AUTOSAR XML (schema 00051)
package /MyReceivingSWC
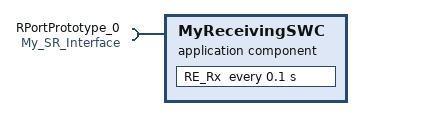
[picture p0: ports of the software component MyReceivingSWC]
  application sw component type MyReceivingSWC
    require port RPortPrototype_0: required-interface=My_SR_Interface
    behavior RxSwcInternalBehavior: data-type-mapping=MyDataTypeMappingSet, supports-multiple-instantiation=true
      timing event TE_RX: start-on-event=RE_Rx, period=0.1
      runnable RE_Rx: symbol=RE_Rx_func
        data-read-access:
          access DRA_DE_MyDataElement_0: accessed-variable=RPortPrototype_0.DE_MyDataElement
